AUTOSAR XML (schema 4-3-0)
package /ComponentTypes
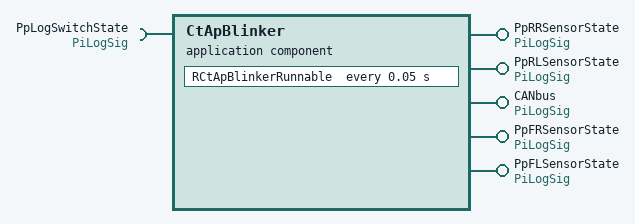
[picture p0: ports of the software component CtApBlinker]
  application sw component type CtApBlinker
    require port PpLogSwitchState: nonqueued-receiver-com-spec{data-element=DePiLedState, filter=data-filter-type=ALWAYS, init-value=0}, required-interface=PiLogSig
    5 x provide port, all with nonqueued-sender-com-spec{data-element=DePiLedState, init-value=0}, provided-interface=PiLogSig:
      PpRRSensorState
      PpRLSensorState
      CANbus
      PpFRSensorState
      PpFLSensorState
    behavior CtApBlinker_InternalBehavior
      timing event TMT_RCtApBlinkerRunnable: start-on-event=RCtApBlinkerRunnable, period=0.05
      runnable RCtApBlinkerRunnable
        data-receive-point-by-arguments:
          access REC_PpLogSwitchState_DePiLedState: accessed-variable=PpLogSwitchState.DePiLedState
        data-send-points:
          5 x access:
            SEND_CANbus_DePiLedState: accessed-variable=CANbus.DePiLedState
            SEND_PpFLSensorState_DePiLedState: accessed-variable=PpFLSensorState.DePiLedState
            SEND_PpFRSensorState_DePiLedState: accessed-variable=PpFRSensorState.DePiLedState
            SEND_PpRLSensorState_DePiLedState: accessed-variable=PpRLSensorState.DePiLedState
            SEND_PpRRSensorState_DePiLedState: accessed-variable=PpRRSensorState.DePiLedState
  swc implementation CtApBlinker_Implementation: behavior=CtApBlinker_InternalBehavior
